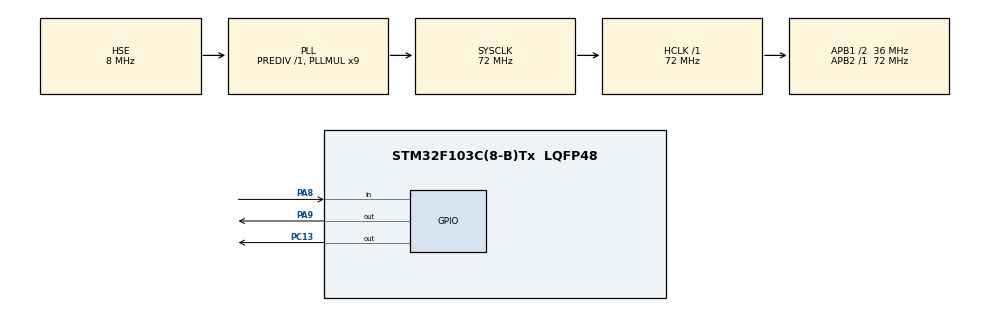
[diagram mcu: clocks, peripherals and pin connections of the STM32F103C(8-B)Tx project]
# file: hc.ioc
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Mcu.Family=STM32F1
Mcu.Name=STM32F103C(8-B)Tx
Mcu.Package=LQFP48
NVIC.PriorityGroup=NVIC_PRIORITYGROUP_4
PA13.Mode=Serial_Wire
PA13.Signal=SYS_JTMS-SWDIO
PA14.Mode=Serial_Wire
PA14.Signal=SYS_JTCK-SWCLK
PA8.Signal=GPIO_Input
PA9.Signal=GPIO_Output
PC13-TAMPER-RTC.Signal=GPIO_Output
PD0-OSC_IN.Mode=HSE-External-Oscillator
PD0-OSC_IN.Signal=RCC_OSC_IN
PD1-OSC_OUT.Mode=HSE-External-Oscillator
PD1-OSC_OUT.Signal=RCC_OSC_OUT
ProjectManager.HeapSize=0x200
ProjectManager.StackSize=0x400
ProjectManager.TargetToolchain=STM32CubeIDE
RCC.AHBFreq_Value=72000000
RCC.APB1CLKDivider=RCC_HCLK_DIV2
RCC.APB1Freq_Value=36000000
RCC.APB1TimFreq_Value=72000000
RCC.APB2Freq_Value=72000000
RCC.APB2TimFreq_Value=72000000
RCC.HCLKFreq_Value=72000000
RCC.PLLMUL=RCC_PLL_MUL9
RCC.PLLSourceVirtual=RCC_PLLSOURCE_HSE
RCC.SYSCLKFreq_VALUE=72000000
RCC.SYSCLKSource=RCC_SYSCLKSOURCE_PLLCLK
RCC.USBFreq_Value=72000000
TIM1.Prescaler=71
VP_TIM1_VS_ClockSourceINT.Mode=Internal
board=custom

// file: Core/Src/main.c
/* USER CODE BEGIN Header */
/**
 ******************************************************************************
 * @file           : main.c
 * @brief          : Main program body
 ******************************************************************************
 */
/* USER CODE END Header */

#include "main.h"

TIM_HandleTypeDef htim1;

void SystemClock_Config(void);
static void MX_GPIO_Init(void);
static void MX_TIM1_Init(void);
/* USER CODE BEGIN PFP */
void Sensor_LED_Control(void);
float HC_SR04_GetDistance(void);
void LED_Control(float distance);
/* USER CODE END PFP */

/* USER CODE BEGIN 0 */
void Sensor_LED_Control(void)
{
  // Sensörden oku (PA8)
  GPIO_PinState sensorValue = HAL_GPIO_ReadPin(GPIOA, GPIO_PIN_8);

  // Debug: Sensör değerini kontrol et
  static uint32_t debug_counter = 0;
  debug_counter++;

  // Her 1000 döngüde bir debug bilgisi ver
  if (debug_counter % 1000 == 0)
  {
    // Sensör değeri HIGH ise LED yanacak, LOW ise sönecek
    if (sensorValue == GPIO_PIN_SET)
    {
      // Sensör HIGH - LED yanmalı
      HAL_GPIO_WritePin(GPIOC, GPIO_PIN_13, GPIO_PIN_RESET); // LED ON
    }
    else
    {
      // Sensör LOW - LED sönmeli
      HAL_GPIO_WritePin(GPIOC, GPIO_PIN_13, GPIO_PIN_SET); // LED OFF
    }
  }

  /* Eğer sensör algıladığında LOW veriyorsa yukarıdaki if'in tersini kullan:
  if (sensorValue == GPIO_PIN_RESET)
  {
      HAL_GPIO_WritePin(GPIOC, GPIO_PIN_13, GPIO_PIN_RESET); // LED ON
  }
  else
  {
      HAL_GPIO_WritePin(GPIOC, GPIO_PIN_13, GPIO_PIN_SET);   // LED OFF
  }
  */
}

// HC-SR04 Mesafe ölçme fonksiyonu
float HC_SR04_GetDistance(void)
{
  uint32_t start_time, end_time, duration;
  float distance_cm;

  // Trig pinini 10us HIGH yap (tetikleme)
  HAL_GPIO_WritePin(GPIOA, GPIO_PIN_9, GPIO_PIN_SET);
  HAL_Delay(1); // 10us yerine 1ms (daha güvenli)
  HAL_GPIO_WritePin(GPIOA, GPIO_PIN_9, GPIO_PIN_RESET);

  // Echo pininin HIGH olmasını bekle
  while (HAL_GPIO_ReadPin(GPIOA, GPIO_PIN_8) == GPIO_PIN_RESET)
    ;

  // Timer'ı başlat
  HAL_TIM_Base_Start(&htim1);
  start_time = __HAL_TIM_GET_COUNTER(&htim1);

  // Echo pininin LOW olmasını bekle
  while (HAL_GPIO_ReadPin(GPIOA, GPIO_PIN_8) == GPIO_PIN_SET)
    ;

  // Timer'ı durdur
  end_time = __HAL_TIM_GET_COUNTER(&htim1);
  HAL_TIM_Base_Stop(&htim1);

  // Süreyi hesapla (timer 1MHz'de çalışıyor)
  duration = end_time - start_time;

  // Mesafeyi hesapla (ses hızı = 343 m/s)
  // distance = (duration * 343) / (2 * 1000000) * 100
  distance_cm = (duration * 0.0343) / 2.0;

  return distance_cm;
}

// LED kontrol fonksiyonu
void LED_Control(float distance)
{
  if (distance < 20.0) // 20cm'den yakın mesafede
  {
    HAL_GPIO_WritePin(GPIOC, GPIO_PIN_13, GPIO_PIN_RESET); // LED ON
  }
  else
  {
    HAL_GPIO_WritePin(GPIOC, GPIO_PIN_13, GPIO_PIN_SET); // LED OFF
  }
}
/* USER CODE END 0 */

int main(void)
{
  /* MCU Configuration--------------------------------------------------------*/
  HAL_Init();
  SystemClock_Config();

  /* Initialize all configured peripherals */
  MX_GPIO_Init();
  MX_TIM1_Init();

  /* USER CODE BEGIN 2 */
  // HC-SR04 başlangıç ayarları
  HAL_GPIO_WritePin(GPIOA, GPIO_PIN_9, GPIO_PIN_RESET); // Trig başlangıçta LOW
  /* USER CODE END 2 */

  /* Infinite loop */
  while (1)
  {
    float distance = HC_SR04_GetDistance();
    LED_Control(distance);
    HAL_Delay(100); // 100ms bekle
  }
}

void SystemClock_Config(void)
{
  RCC_OscInitTypeDef RCC_OscInitStruct = {0};
  RCC_ClkInitTypeDef RCC_ClkInitStruct = {0};

  /** Initializes the RCC Oscillators */
  RCC_OscInitStruct.OscillatorType = RCC_OSCILLATORTYPE_HSE;
  RCC_OscInitStruct.HSEState = RCC_HSE_ON;
  RCC_OscInitStruct.HSEPredivValue = RCC_HSE_PREDIV_DIV1;
  RCC_OscInitStruct.HSIState = RCC_HSI_ON;
  RCC_OscInitStruct.PLL.PLLState = RCC_PLL_ON;
  RCC_OscInitStruct.PLL.PLLSource = RCC_PLLSOURCE_HSE;
  RCC_OscInitStruct.PLL.PLLMUL = RCC_PLL_MUL9;
  if (HAL_RCC_OscConfig(&RCC_OscInitStruct) != HAL_OK)
  {
    Error_Handler();
  }

  /** Initializes the CPU, AHB and APB buses clocks */
  RCC_ClkInitStruct.ClockType = RCC_CLOCKTYPE_HCLK | RCC_CLOCKTYPE_SYSCLK | RCC_CLOCKTYPE_PCLK1 | RCC_CLOCKTYPE_PCLK2;
  RCC_ClkInitStruct.SYSCLKSource = RCC_SYSCLKSOURCE_PLLCLK;
  RCC_ClkInitStruct.AHBCLKDivider = RCC_SYSCLK_DIV1;
  RCC_ClkInitStruct.APB1CLKDivider = RCC_HCLK_DIV2;
  RCC_ClkInitStruct.APB2CLKDivider = RCC_HCLK_DIV1;

  if (HAL_RCC_ClockConfig(&RCC_ClkInitStruct, FLASH_LATENCY_2) != HAL_OK)
  {
    Error_Handler();
  }
}

static void MX_TIM1_Init(void)
{
  TIM_ClockConfigTypeDef sClockSourceConfig = {0};
  TIM_MasterConfigTypeDef sMasterConfig = {0};

  htim1.Instance = TIM1;
  htim1.Init.Prescaler = 71;
  htim1.Init.CounterMode = TIM_COUNTERMODE_UP;
  htim1.Init.Period = 65535;
  htim1.Init.ClockDivision = TIM_CLOCKDIVISION_DIV1;
  htim1.Init.RepetitionCounter = 0;
  htim1.Init.AutoReloadPreload = TIM_AUTORELOAD_PRELOAD_DISABLE;
  if (HAL_TIM_Base_Init(&htim1) != HAL_OK)
  {
    Error_Handler();
  }
  sClockSourceConfig.ClockSource = TIM_CLOCKSOURCE_INTERNAL;
  if (HAL_TIM_ConfigClockSource(&htim1, &sClockSourceConfig) != HAL_OK)
  {
    Error_Handler();
  }
  sMasterConfig.MasterOutputTrigger = TIM_TRGO_RESET;
  sMasterConfig.MasterSlaveMode = TIM_MASTERSLAVEMODE_DISABLE;
  if (HAL_TIMEx_MasterConfigSynchronization(&htim1, &sMasterConfig) != HAL_OK)
  {
    Error_Handler();
  }
}

static void MX_GPIO_Init(void)
{
  GPIO_InitTypeDef GPIO_InitStruct = {0};

  /* GPIO Ports Clock Enable */
  __HAL_RCC_GPIOC_CLK_ENABLE();
  __HAL_RCC_GPIOD_CLK_ENABLE();
  __HAL_RCC_GPIOA_CLK_ENABLE();

  /*Configure GPIO pin Output Level */
  HAL_GPIO_WritePin(GPIOC, GPIO_PIN_13, GPIO_PIN_SET);  // LED başlangıçta OFF
  HAL_GPIO_WritePin(GPIOA, GPIO_PIN_5, GPIO_PIN_SET);   // PA5 LED başlangıçta OFF
  HAL_GPIO_WritePin(GPIOA, GPIO_PIN_9, GPIO_PIN_RESET); // Sensör başlangıçta kapalı

  /*Configure GPIO pin : PC13 (LED) */
  GPIO_InitStruct.Pin = GPIO_PIN_13;
  GPIO_InitStruct.Mode = GPIO_MODE_OUTPUT_PP;
  GPIO_InitStruct.Pull = GPIO_PULLDOWN;         // Pull-down ekle
  GPIO_InitStruct.Speed = GPIO_SPEED_FREQ_HIGH; // Hızlı yap
  HAL_GPIO_Init(GPIOC, &GPIO_InitStruct);

  /*Configure GPIO pin : PA8 (Sensor IN) */
  GPIO_InitStruct.Pin = GPIO_PIN_8;
  GPIO_InitStruct.Mode = GPIO_MODE_INPUT;
  GPIO_InitStruct.Pull = GPIO_NOPULL;
  HAL_GPIO_Init(GPIOA, &GPIO_InitStruct);

  /*Configure GPIO pin : PA9 (Sensor Power OUT) */
  GPIO_InitStruct.Pin = GPIO_PIN_9;
  GPIO_InitStruct.Mode = GPIO_MODE_OUTPUT_PP;
  GPIO_InitStruct.Pull = GPIO_NOPULL;
  GPIO_InitStruct.Speed = GPIO_SPEED_FREQ_LOW;
  HAL_GPIO_Init(GPIOA, &GPIO_InitStruct);
}

/* Error Handler */
void Error_Handler(void)
{
  __disable_irq();
  while (1)
  {
  }
}
